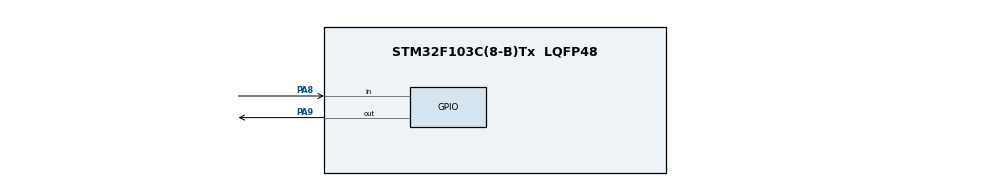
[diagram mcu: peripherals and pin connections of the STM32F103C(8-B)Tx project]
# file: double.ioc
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Mcu.Family=STM32F1
Mcu.Name=STM32F103C(8-B)Tx
Mcu.Package=LQFP48
NVIC.PriorityGroup=NVIC_PRIORITYGROUP_4
PA13.Mode=Serial_Wire
PA13.Signal=SYS_JTMS-SWDIO
PA14.Mode=Serial_Wire
PA14.Signal=SYS_JTCK-SWCLK
PA8.GPIO_PuPd=GPIO_PULLUP
PA8.Signal=GPIO_Input
PA9.Signal=GPIO_Output
ProjectManager.HeapSize=0x200
ProjectManager.StackSize=0x400
ProjectManager.TargetToolchain=MDK-ARM V5.32
RCC.APB1Freq_Value=8000000
RCC.APB2Freq_Value=8000000
board=custom

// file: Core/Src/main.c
/* USER CODE BEGIN Header */
/**
  ******************************************************************************
  * @file           : main.c
  * @brief          : Main program body
  ******************************************************************************
  * @attention
  *
  * Copyright (c) 2026 STMicroelectronics.
  * All rights reserved.
  *
  * This software is licensed under terms that can be found in the LICENSE file
  * in the root directory of this software component.
  * If no LICENSE file comes with this software, it is provided AS-IS.
  *
  ******************************************************************************
  */
/* USER CODE END Header */
#include "main.h"
#include "gpio.h"

void SystemClock_Config(void);

int main(void)
{

  /* USER CODE BEGIN 1 */

    static uint32_t  last_time=0;
    static uint8_t  last_state=GPIO_PIN_SET;
    static uint8_t  current_state=GPIO_PIN_SET;
    volatile int count=0;
    static uint32_t first_time=0;
  /* USER CODE END 1 */

  /* MCU Configuration--------------------------------------------------------*/

  /* Reset of all peripherals, Initializes the Flash interface and the Systick. */
  HAL_Init();

  /* Configure the system clock */
  SystemClock_Config();

  /* Initialize all configured peripherals */
  MX_GPIO_Init();

  /* Infinite loop */
  /* USER CODE BEGIN WHILE */
  while (1)
  {
       uint32_t current_time=HAL_GetTick();
       uint8_t read_state=HAL_GPIO_ReadPin(GPIOA,GPIO_PIN_8);
       if(read_state!=last_state)
       {
        last_time=current_time;
        last_state=read_state;

       }
       if(current_time-last_time>20)
       {
        if(read_state==GPIO_PIN_RESET&&current_state==GPIO_PIN_SET)
         {
          current_state=GPIO_PIN_RESET;
          count++;
          if(count==1)
          {
            first_time=current_time;
          }
          if(count==2&&current_time-first_time<500)
           {
            HAL_GPIO_TogglePin(GPIOA,GPIO_PIN_9);
            count=0;

           }
          }
        if(read_state==GPIO_PIN_SET&&current_state==GPIO_PIN_RESET)
         {
          current_state=GPIO_PIN_SET;
         }

       }
       if(count==1&&current_time-first_time>500)
        {
          count=0;
        }

    /* USER CODE END WHILE */

  }
}

void SystemClock_Config(void)
{
  RCC_OscInitTypeDef RCC_OscInitStruct = {0};
  RCC_ClkInitTypeDef RCC_ClkInitStruct = {0};

  /** Initializes the RCC Oscillators according to the specified parameters
  * in the RCC_OscInitTypeDef structure.
  */
  RCC_OscInitStruct.OscillatorType = RCC_OSCILLATORTYPE_HSI;
  RCC_OscInitStruct.HSIState = RCC_HSI_ON;
  RCC_OscInitStruct.HSICalibrationValue = RCC_HSICALIBRATION_DEFAULT;
  RCC_OscInitStruct.PLL.PLLState = RCC_PLL_NONE;
  if (HAL_RCC_OscConfig(&RCC_OscInitStruct) != HAL_OK)
  {
    Error_Handler();
  }

  /** Initializes the CPU, AHB and APB buses clocks
  */
  RCC_ClkInitStruct.ClockType = RCC_CLOCKTYPE_HCLK|RCC_CLOCKTYPE_SYSCLK
                              |RCC_CLOCKTYPE_PCLK1|RCC_CLOCKTYPE_PCLK2;
  RCC_ClkInitStruct.SYSCLKSource = RCC_SYSCLKSOURCE_HSI;
  RCC_ClkInitStruct.AHBCLKDivider = RCC_SYSCLK_DIV1;
  RCC_ClkInitStruct.APB1CLKDivider = RCC_HCLK_DIV1;
  RCC_ClkInitStruct.APB2CLKDivider = RCC_HCLK_DIV1;

  if (HAL_RCC_ClockConfig(&RCC_ClkInitStruct, FLASH_LATENCY_0) != HAL_OK)
  {
    Error_Handler();
  }
}

void Error_Handler(void)
{
  __disable_irq();
  while (1)
  {
  }
}
